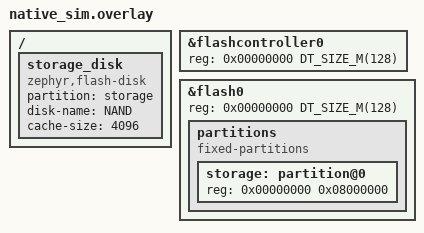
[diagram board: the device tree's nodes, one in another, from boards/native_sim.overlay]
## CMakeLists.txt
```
# SPDX-License-Identifier: Apache-2.0

cmake_minimum_required(VERSION 3.20.0)
find_package(Zephyr REQUIRED HINTS $ENV{ZEPHYR_BASE})
project(ext2tests)

FILE(GLOB app_sources src/*.c)
FILE(GLOB common_sources
  ../common/test_fs_util.c
  ../common/test_fs_mkfs.c
  ../common/test_fs_basic.c
  ../common/test_fs_dirops.c
  ../common/test_fs_open_flags.c
  ../common/test_fs_mount_flags.c
)
target_sources(app PRIVATE
  ${app_sources}
  ${common_sources}
)
```

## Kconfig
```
# SPDX-License-Identifier: Apache-2.0
# Copyright (c) 2023 Antmicro

mainmenu "Ext2 tests"

source "Kconfig.zephyr"

config APP_TEST_BIG
	bool "Make tests with larger file systems"
```

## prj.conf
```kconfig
CONFIG_FILE_SYSTEM=y
CONFIG_FILE_SYSTEM_EXT2=y
CONFIG_FILE_SYSTEM_MKFS=y

CONFIG_DISK_ACCESS=y
CONFIG_DISK_DRIVER_RAM=y

CONFIG_TEST_RANDOM_GENERATOR=y

CONFIG_ZTEST=y
CONFIG_ZTEST_STACK_SIZE=4096
```

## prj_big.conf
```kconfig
CONFIG_FILE_SYSTEM=y
CONFIG_FILE_SYSTEM_EXT2=y
CONFIG_FILE_SYSTEM_MKFS=y

CONFIG_DISK_ACCESS=y
CONFIG_DISK_DRIVER_RAM=y

CONFIG_EXT2_MAX_BLOCK_COUNT=20

CONFIG_TEST_RANDOM_GENERATOR=y

CONFIG_ZTEST=y
CONFIG_ZTEST_STACK_SIZE=4096

CONFIG_APP_TEST_BIG=y
```

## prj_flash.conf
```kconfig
CONFIG_FILE_SYSTEM=y
CONFIG_FILE_SYSTEM_EXT2=y
CONFIG_FILE_SYSTEM_MKFS=y

CONFIG_DISK_ACCESS=y
CONFIG_DISK_DRIVER_FLASH=y

CONFIG_TEST_RANDOM_GENERATOR=y

CONFIG_ZTEST=y
CONFIG_ZTEST_STACK_SIZE=4096
```

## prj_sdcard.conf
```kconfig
CONFIG_FILE_SYSTEM=y
CONFIG_FILE_SYSTEM_EXT2=y
CONFIG_FILE_SYSTEM_MKFS=y

CONFIG_SPI=y

CONFIG_DISK_ACCESS=y
CONFIG_DISK_DRIVER_SDMMC=y

CONFIG_EXT2_DISK_STARTING_SECTOR=34

CONFIG_TEST_RANDOM_GENERATOR=y

CONFIG_ZTEST=y
CONFIG_ZTEST_STACK_SIZE=4096
```

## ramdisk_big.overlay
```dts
/*
 * Copyright (c) 2023 Nordic Semiconductor ASA
 *
 * SPDX-License-Identifier: Apache-2.0
 */

/ {
	ramdisk0 {
		compatible = "zephyr,ram-disk";
		disk-name = "RAM";
		sector-size = <512>;
		sector-count = <18000>;
	};
};
```

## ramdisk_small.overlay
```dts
/*
 * Copyright (c) 2023 Nordic Semiconductor ASA
 *
 * SPDX-License-Identifier: Apache-2.0
 */

/ {
	ramdisk0 {
		compatible = "zephyr,ram-disk";
		disk-name = "RAM";
		sector-size = <512>;
		sector-count = <400>;
	};
};
```

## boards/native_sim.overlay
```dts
/*
 * Copyright (c) 2023 Antmicro
 *
 * SPDX-License-Identifier: Apache-2.0
 */

&flashcontroller0 {
	reg = <0x00000000 DT_SIZE_M(128)>;
};

&flash0 {
	reg = <0x00000000 DT_SIZE_M(128)>;
	partitions {
		compatible = "fixed-partitions";
		#address-cells = <1>;
		#size-cells = <1>;

		storage: partition@0 {
			reg = <0x00000000 0x08000000>;
		};
	};
};

/ {
	storage_disk {
		compatible = "zephyr,flash-disk";
		partition = <&storage>;
		disk-name = "NAND";
		cache-size = <4096>;
	};
};
```

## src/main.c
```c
/*
 * Copyright (c) 2023 Antmicro
 *
 * SPDX-License-Identifier: Apache-2.0
 */

#include <zephyr/ztest.h>
#include <zephyr/fs/fs.h>

#include "utils.h"

#ifdef CONFIG_DISK_DRIVER_RAM
	#define STORAGE_DEVICE "RAM"
#elif CONFIG_DISK_DRIVER_FLASH
	#define STORAGE_DEVICE "NAND"
#elif CONFIG_DISK_DRIVER_SDMMC
	#define STORAGE_DEVICE "SDMMC"
#endif

/* All tests must use this structure to mount file system. After each test this structure is cleaned
 * to allow for running next tests unaffected by previous one.
 */
struct fs_mount_t testfs_mnt = {
	.type = FS_EXT2,
	.mnt_point = "/sml",
	.storage_dev = STORAGE_DEVICE,
	.flags = 0,
};

static void before_test(void *f)
{
	ARG_UNUSED(f);

	zassert_equal(wipe_partition((uintptr_t)testfs_mnt.storage_dev), TC_PASS,
			"Failed to clean partition");
	testfs_mnt.flags = 0;
}

static void after_test(void *f)
{
	ARG_UNUSED(f);

	/* Unmount file system */
	fs_unmount(&testfs_mnt);
}

ZTEST_SUITE(ext2tests, NULL, NULL, before_test, after_test, NULL);
```

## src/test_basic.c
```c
/*
 * Copyright (c) 2023 Antmicro
 *
 * SPDX-License-Identifier: Apache-2.0
 */

#include <zephyr/ztest.h>
#include <zephyr/fs/fs.h>

#include "utils.h"

void test_fs_basic(void);

/* Expected by test_fs_basic() */
struct fs_mount_t *fs_basic_test_mp = &testfs_mnt;

ZTEST(ext2tests, test_basic)
{
	/* Common basic tests.
	 * (File system is mounted and unmounted during that test.)
	 */
	test_fs_basic();
}
```

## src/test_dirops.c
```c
/*
 * Copyright (c) 2023 Antmicro
 *
 * SPDX-License-Identifier: Apache-2.0
 */

#include <zephyr/ztest.h>
#include <zephyr/fs/fs.h>

#include "utils.h"

void test_fs_dirops(void);

/* Mount structure needed by test_fs_basic tests. */
struct fs_mount_t *fs_dirops_test_mp = &testfs_mnt;

ZTEST(ext2tests, test_dirops)
{
	struct fs_mount_t *mp = &testfs_mnt;
	struct fs_dirent de;

	zassert_equal(fs_mount(mp), 0, "Mount failed");

	/* 'lost+found' directory is created automatically. test_fs_dirops expects empty root
	 * directory hence we have to remove it before starting test.
	 */
	if (fs_stat("/sml/lost+found", &de) == 0) {
		zassert_equal(fs_unlink("/sml/lost+found"), 0, "unlink failed");
	}
	zassert_equal(fs_unmount(mp), 0, "Unount failed");

	/* Common dirops tests.
	 * (File system is mounted and unmounted during that test.)
	 */
	test_fs_dirops();
}
```

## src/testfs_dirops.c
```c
/*
 * Copyright (c) 2023 Antmicro
 *
 * SPDX-License-Identifier: Apache-2.0
 */

#include <zephyr/ztest.h>
#include <zephyr/fs/fs.h>

#include "utils.h"

ZTEST(ext2tests, test_dirops_basic)
{
	struct fs_mount_t *mp = &testfs_mnt;

	zassert_equal(fs_mount(mp), 0, "Mount failed");

	struct fs_file_t file;
	struct fs_dirent stat;

	fs_file_t_init(&file);

	/* Create some directories */
	zassert_equal(fs_mkdir("/sml/dir1"), 0, "Create dir1 failed");
	zassert_equal(fs_mkdir("/sml/dir2"), 0, "Create dir2 failed");

	/* Create some files */
	zassert_equal(fs_open(&file, "/sml/file1", FS_O_CREATE), 0, "Create file1 failed");
	zassert_equal(fs_close(&file), 0, "Close file error");
	zassert_equal(fs_open(&file, "/sml/dir1/file2", FS_O_CREATE), 0, "Create file2 failed");
	zassert_equal(fs_close(&file), 0, "Close file error");
	zassert_equal(fs_open(&file, "/sml/dir2/file3", FS_O_CREATE), 0, "Create file3 failed");
	zassert_equal(fs_close(&file), 0, "Close file error");

	/* Check if directories will open as files */
	zassert_equal(fs_open(&file, "/sml/dir1", 0), -EINVAL, "Should return error");
	zassert_equal(fs_open(&file, "/sml/dir2", 0), -EINVAL, "Should return error");

	/* Check directories with stat */
	zassert_equal(fs_stat("/sml/dir1", &stat), 0, "Stat dir1 failed");
	zassert_equal(stat.type, FS_DIR_ENTRY_DIR, "Wrong type");
	zassert_equal(stat.size, 0, "Wrong directory size");
	zassert_mem_equal(stat.name, "dir1", 5, "Wrong directory name");

	zassert_equal(fs_stat("/sml/dir2", &stat), 0, "Stat dir2 failed");
	zassert_equal(stat.type, FS_DIR_ENTRY_DIR, "Wrong type");
	zassert_equal(stat.size, 0, "Wrong directory size");
	zassert_mem_equal(stat.name, "dir2", 5, "Wrong directory name");

	/* Check if files will open correctly */
	zassert_equal(fs_open(&file, "/sml/file1", 0), 0, "Open file1 should succeed");
	zassert_equal(fs_close(&file), 0, "Close file error");
	zassert_equal(fs_open(&file, "/sml/dir1/file2", 0), 0, "Open file2 should succeed");
	zassert_equal(fs_close(&file), 0, "Close file error");
	zassert_equal(fs_open(&file, "/sml/dir2/file3", 0), 0, "Open file3 should succeed");
	zassert_equal(fs_close(&file), 0, "Close file error");

	/* Check files with stat */
	zassert_equal(fs_stat("/sml/file1", &stat), 0, "Stat file1 failed");
	zassert_equal(stat.type, FS_DIR_ENTRY_FILE, "Wrong type");
	zassert_equal(stat.size, 0, "Wrong file size");
	zassert_mem_equal(stat.name, "file1", 6, "Wrong file name");

	zassert_equal(fs_stat("/sml/dir1/file2", &stat), 0, "Stat file1 failed");
	zassert_equal(stat.type, FS_DIR_ENTRY_FILE, "Wrong type");
	zassert_equal(stat.size, 0, "Wrong file size");
	zassert_mem_equal(stat.name, "file2", 6, "Wrong file name");

	zassert_equal(fs_stat("/sml/dir2/file3", &stat), 0, "Stat file1 failed");
	zassert_equal(stat.type, FS_DIR_ENTRY_FILE, "Wrong type");
	zassert_equal(stat.size, 0, "Wrong file size");
	zassert_mem_equal(stat.name, "file3", 6, "Wrong file name");

	/* Check for some nonexisting files */
	zassert_equal(fs_open(&file, "/sml/file2", 0), -ENOENT, "Should not exist");
	zassert_equal(fs_open(&file, "/sml/file3", 0), -ENOENT, "Should not exist");
	zassert_equal(fs_open(&file, "/sml/dir1/file1", 0), -ENOENT, "Should not exist");
	zassert_equal(fs_open(&file, "/sml/dir1/file3", 0), -ENOENT, "Should not exist");
	zassert_equal(fs_open(&file, "/sml/dir2/file1", 0), -ENOENT, "Should not exist");
	zassert_equal(fs_open(&file, "/sml/dir2/file2", 0), -ENOENT, "Should not exist");

	zassert_equal(fs_unmount(mp), 0, "Unmount failed");
}
```

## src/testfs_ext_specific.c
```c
/*
 * Copyright (c) 2023 Antmicro
 *
 * SPDX-License-Identifier: Apache-2.0
 */

#include <zephyr/ztest.h>
#include <zephyr/fs/fs.h>
#include <zephyr/fs/ext2.h>
#include "utils.h"
#include "../../common/test_fs_util.h"

uint32_t calculate_blocks(uint32_t freeb, uint32_t B)
{
	uint32_t blocks = 0;

	if (freeb <= 12) {
		return freeb;
	}

	blocks += 12;
	freeb -= 12 + 1; /* direct blocks + top block of first level table */

	if (freeb <= B) {
		return blocks + freeb;
	}

	blocks += B;
	freeb -= B + 1; /* 1st level blocks + top block of second level table */

	if (freeb <= B * (B + 1)) {
		uint32_t n = freeb / (B + 1);
		uint32_t r = freeb % (B + 1);
		uint32_t partial = r > 0 ? 1 : 0;

		return blocks + n * B + r - partial;
	}
	return blocks;
	/* TODO: revisit this and extend when 3rd level blocks will be possible */
}

static void write_to_file(const char *file_path, uint32_t bytes_to_write)
{
	int64_t ret = 0;
	struct fs_file_t file;
	struct fs_dirent entry;

	fs_file_t_init(&file);
	ret = fs_open(&file, file_path, FS_O_RDWR | FS_O_CREATE);
	zassert_equal(ret, 0, "File open failed (ret=%d)", ret);

	ret = testfs_write_incrementing(&file, 0, bytes_to_write);
	zassert_equal(ret, bytes_to_write, "Different number of bytes written %ld (expected %ld)",
			ret, bytes_to_write);

	ret = fs_close(&file);
	zassert_equal(ret, 0, "File close failed (ret=%d)", ret);


	/* Check file size */
	ret = fs_stat(file_path, &entry);
	zassert_equal(ret, 0, "File stat failed (ret=%d)", ret);
	zassert_equal(entry.size, bytes_to_write,
			"Wrong file size %d (expected %d)", entry.size,
			bytes_to_write);

	fs_file_t_init(&file);
	ret = fs_open(&file, file_path, FS_O_READ);
	zassert_equal(ret, 0, "File open failed (ret=%d)", ret);


	ret = testfs_verify_incrementing(&file, 0, bytes_to_write);
	zassert_equal(ret, bytes_to_write, "Different number of bytes read %ld (expected %ld)",
			ret, bytes_to_write);

	ret = fs_close(&file);
	zassert_equal(ret, 0, "File close failed (ret=%d)", ret);
}

static void truncate_file(const char *file_path, uint32_t new_size)
{
	int64_t ret = 0;
	struct fs_file_t file;
	struct fs_dirent entry;

	fs_file_t_init(&file);

	TC_PRINT("Truncating to %d\n", new_size);

	ret = fs_open(&file, file_path, FS_O_RDWR);
	zassert_equal(ret, 0, "File open failed (ret=%d)", ret);

	ret = fs_truncate(&file, new_size);
	zassert_equal(ret, 0, "File truncate failed (ret=%d)", ret);

	ret = fs_stat(file_path, &entry);
	zassert_equal(ret, 0, "File stat failed (ret=%d)", ret);
	zassert_equal(entry.size, new_size,
			"Wrong file size %d (expected %d)", entry.size, new_size);

	ret = fs_seek(&file, 0, FS_SEEK_SET);
	zassert_equal(ret, 0, "File seek failed (ret=%d)", ret);

	ret = testfs_verify_incrementing(&file, 0, new_size);
	zassert_equal(ret, new_size, "Different number of bytes read %ld (expected %ld)",
			ret, new_size);

	ret = fs_close(&file);
	zassert_equal(ret, 0, "File close failed (ret=%d)", ret);
}

void writing_test(struct ext2_cfg *config)
{
	int64_t ret = 0;
	struct fs_statvfs sbuf;
	struct fs_mount_t *mp = &testfs_mnt;
	static const char *file_path = "/sml/file";

	ret = fs_mkfs(FS_EXT2, (uintptr_t)mp->storage_dev, config, 0);
	zassert_equal(ret, 0, "Failed to mkfs with 2K blocks");

	mp->flags = FS_MOUNT_FLAG_NO_FORMAT;
	ret = fs_mount(mp);
	zassert_equal(ret, 0, "Mount failed (ret=%d)", ret);

	ret = fs_statvfs(mp->mnt_point, &sbuf);
	zassert_equal(ret, 0, "Expected success (ret=%d)", ret);

	/* Calculate how many numbers will be written (use all available memory) */
	uint32_t freeb = sbuf.f_bfree;
	uint32_t bsize = sbuf.f_bsize;
	uint32_t available_blocks = calculate_blocks(freeb, bsize / sizeof(uint32_t));

	uint32_t bytes_to_write = bsize * available_blocks;

	TC_PRINT("Available blocks: %d\nBlock size: %d\nBytes_to_write: %d\n",
			available_blocks, bsize, bytes_to_write);

	write_to_file(file_path, bytes_to_write);

	uint32_t new_size = bytes_to_write;

	while (new_size > 1) {
		new_size = new_size / 8 * 3;
		truncate_file(file_path, new_size);
	}

	ret = fs_unmount(mp);
	zassert_equal(ret, 0, "Unmount failed (ret=%d)", ret);
}

ZTEST(ext2tests, test_indirect_block_removal)
{
	int64_t ret = 0;
	struct fs_statvfs sbuf;
	struct fs_mount_t *mp = &testfs_mnt;
	static const char *file_path = "/sml/file";

	ret = fs_mkfs(FS_EXT2, (uintptr_t)mp->storage_dev, NULL, 0);
	zassert_equal(ret, 0, "Failed to mkfs with 2K blocks");

	mp->flags = FS_MOUNT_FLAG_NO_FORMAT;
	ret = fs_mount(mp);
	zassert_equal(ret, 0, "Mount failed (ret=%d)", ret);

	ret = fs_statvfs(mp->mnt_point, &sbuf);
	zassert_equal(ret, 0, "Expected success (ret=%d)", ret);

	uint32_t bsize = sbuf.f_bsize;

	uint32_t bytes_to_write = bsize * 13;

	TC_PRINT("Block size: %d\nBytes_to_write: %d\n", bsize, bytes_to_write);

	write_to_file(file_path, bytes_to_write);

	/* First truncate will remove all blocks under first indirect block.
	 * Second truncate will remove rest of blocks;
	 * it will check if first indirect block was removed properly.
	 */
	uint32_t sizes[] = {12 * bsize, 0};

	for (int i = 0; i < ARRAY_SIZE(sizes); i++) {
		uint32_t new_size = sizes[i];

		truncate_file(file_path, new_size);
	}

	ret = fs_unmount(mp);
	zassert_equal(ret, 0, "Unmount failed (ret=%d)", ret);
}

ZTEST(ext2tests, test_write_big_file)
{
	writing_test(NULL);
}

#if defined(CONFIG_APP_TEST_BIG)
ZTEST(ext2tests, test_write_big_file_2K)
{
	struct ext2_cfg config = {
		.block_size = 2048,
		.fs_size = 0x2000000,
		.bytes_per_inode = 0,
		.volume_name[0] = 0,
		.set_uuid = false,
	};

	writing_test(&config);
}

ZTEST(ext2tests, test_write_big_file_4K)
{
	struct ext2_cfg config = {
		.block_size = 4096,
		.fs_size = 0x8000000,
		.bytes_per_inode = 0,
		.volume_name[0] = 0,
		.set_uuid = false,
	};

	writing_test(&config);
}
#endif
```

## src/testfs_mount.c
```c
/*
 * Copyright (c) 2023 Antmicro
 *
 * SPDX-License-Identifier: Apache-2.0
 */

#include <zephyr/ztest.h>
#include <zephyr/fs/fs.h>
#include <zephyr/fs/ext2.h>
#include "utils.h"

ZTEST(ext2tests, test_mount_only)
{
	struct fs_mount_t *mp = &testfs_mnt;
	int ret = 0;

	/* Test FS_MOUNT_FLAG_NO_FORMAT flag */
	mp->flags |= FS_MOUNT_FLAG_NO_FORMAT;
	ret = fs_mount(mp);
	TC_PRINT("Mount unformatted with FS_MOUNT_FLAG_NO_FORMAT set\n");
	zassert_false(ret == 0, "Expected failure (ret=%d)", ret);

	/* Test FS_MOUNT_FLAG_READ_ONLY on non-formatted volume*/
	mp->flags = FS_MOUNT_FLAG_READ_ONLY;
	ret = fs_mount(mp);
	TC_PRINT("Mount unformatted with FS_MOUNT_FLAG_READ_ONLY set\n");
	zassert_false(ret == 0, "Expected failure (ret=%d)", ret);

	/* Format volume and add some files/dirs to check read-only flag */
	mp->flags = 0;
	ret = fs_mount(mp);
	TC_PRINT("Mount again to format volume\n");
	zassert_equal(ret, 0, "Expected success (ret=%d)", ret);
	TC_PRINT("Create some file\n");

	ret = fs_unmount(mp);
	zassert_equal(ret, 0, "Expected success (ret=%d)", ret);

	/* Check fs operation on volume mounted with FS_MOUNT_FLAG_READ_ONLY */
	mp->flags = FS_MOUNT_FLAG_READ_ONLY;
	TC_PRINT("Mount as read-only\n");
	ret = fs_mount(mp);
	zassert_equal(ret, 0, "Expected success (ret=%d)", ret);

	ret = fs_unmount(mp);
	zassert_equal(ret, 0, "Expected success (ret=%d)", ret);
}

ZTEST(ext2tests, test_statvfs)
{
	int ret = 0;
	struct fs_statvfs sbuf;
	struct fs_mount_t *mp = &testfs_mnt;
	size_t partition_size = MIN(0x800000, get_partition_size((uintptr_t)mp->storage_dev));

	mp->flags = 0;
	ret = fs_mount(mp);
	zassert_equal(ret, 0, "Expected success (ret=%d)", ret);

	ret = fs_statvfs(mp->mnt_point, &sbuf);
	zassert_equal(ret, 0, "Expected success (ret=%d)", ret);

	TC_PRINT("Mounted file system: bsize:%lu frsize:%lu blocks:%lu, bfree:%lu\n",
			sbuf.f_bsize, sbuf.f_frsize, sbuf.f_blocks, sbuf.f_bfree);

	zassert_equal(sbuf.f_bsize, 1024,
			"Wrong block size %lu (expected %lu)", sbuf.f_bsize, 1024);
	zassert_equal(sbuf.f_frsize, 1024,
			"Wrong frag size %lu (expected %lu)", sbuf.f_frsize, 1024);
	zassert_equal(sbuf.f_blocks, partition_size / 1024,
			"Wrong block count %lu (expected %lu)",
			sbuf.f_blocks, partition_size / 1024);

	ret = fs_unmount(mp);
	zassert_equal(ret, 0, "Expected success (ret=%d)", ret);
}

/* Tests from common directory */

void test_fs_mkfs_simple(void);

/* Global variables expected by tests */
struct fs_mount_t *fs_mkfs_mp = &testfs_mnt;
const int fs_mkfs_type = FS_EXT2;
uintptr_t fs_mkfs_dev_id;
int fs_mkfs_flags;

ZTEST(ext2tests, test_mkfs_simple)
{
	struct fs_mount_t *mp = &testfs_mnt;

	fs_mkfs_dev_id = (uintptr_t) mp->storage_dev;
	fs_mkfs_flags = 0;
	test_fs_mkfs_simple();
}

void mkfs_custom_config(struct ext2_cfg *cfg)
{
	int ret = 0;
	struct fs_statvfs sbuf;
	struct fs_mount_t *mp = &testfs_mnt;
	size_t partition_size = MIN(cfg->fs_size, get_partition_size((uintptr_t)mp->storage_dev));

	ret = fs_mkfs(FS_EXT2, (uintptr_t)mp->storage_dev, cfg, 0);
	zassert_equal(ret, 0, "Failed to mkfs with 2K blocks");

	mp->flags = FS_MOUNT_FLAG_NO_FORMAT;
	ret = fs_mount(mp);
	zassert_equal(ret, 0, "Mount failed (ret=%d)", ret);

	ret = fs_statvfs(mp->mnt_point, &sbuf);
	zassert_equal(ret, 0, "Statvfs failed (ret=%d)", ret);

	TC_PRINT("Mounted file system: bsize:%lu frsize:%lu blocks:%lu, bfree:%lu\n",
			sbuf.f_bsize, sbuf.f_frsize, sbuf.f_blocks, sbuf.f_bfree);

	zassert_equal(sbuf.f_bsize, cfg->block_size,
			"Wrong block size %lu (expected %lu)", sbuf.f_bsize, cfg->block_size);
	zassert_equal(sbuf.f_frsize, cfg->block_size,
			"Wrong frag size %lu (expected %lu)", sbuf.f_frsize, cfg->block_size);
	zassert_equal(sbuf.f_blocks, partition_size / cfg->block_size,
			"Wrong block count %lu (expected %lu)",
			sbuf.f_blocks, partition_size / cfg->block_size);

	ret = fs_unmount(mp);
	zassert_equal(ret, 0, "Unmount failed (ret=%d)", ret);
}

#if defined(CONFIG_APP_TEST_BIG)
ZTEST(ext2tests, test_mkfs_custom_2K)
{
	struct ext2_cfg config = {
		.block_size = 2048,
		.fs_size = 0x2000000,
		.bytes_per_inode = 0,
		.volume_name[0] = 0,
		.set_uuid = false,
	};

	mkfs_custom_config(&config);
}

ZTEST(ext2tests, test_mkfs_custom_4K)
{
	struct ext2_cfg config = {
		.block_size = 4096,
		.fs_size = 0x8000000,
		.bytes_per_inode = 0,
		.volume_name[0] = 0,
		.set_uuid = false,
	};

	mkfs_custom_config(&config);
}
#endif
```

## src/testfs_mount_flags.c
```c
/*
 * Copyright (c) 2023 Antmicro
 *
 * SPDX-License-Identifier: Apache-2.0
 */

#include <zephyr/ztest.h>
#include <zephyr/fs/fs.h>
#include <zephyr/fs/ext2.h>

#include "utils.h"

void test_fs_mount_flags(void);

/* Global variable expected by tests */
struct fs_mount_t *mount_flags_mp = &testfs_mnt;

ZTEST(ext2tests, test_mount_flags)
{
	test_fs_mount_flags();
}
```

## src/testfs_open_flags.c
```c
/*
 * Copyright (c) 2023 Antmicro
 *
 * SPDX-License-Identifier: Apache-2.0
 */

#include <zephyr/ztest.h>
#include <zephyr/fs/fs.h>
#include <zephyr/fs/ext2.h>

#include "utils.h"

void test_fs_open_flags(void);

/* Expected by test_fs_open_flags() */
const char *test_fs_open_flags_file_path = "/sml/open_flags_file";

ZTEST(ext2tests, test_open_flags)
{
	struct fs_mount_t *mp = &testfs_mnt;

	zassert_equal(fs_mount(mp), 0, "Failed to mount partition");

	test_fs_open_flags();

	zassert_equal(fs_unmount(mp), 0, "Failed to unmount partition");
}

ZTEST(ext2tests, test_open_flags_2K)
{
	int ret = 0;
	struct fs_mount_t *mp = &testfs_mnt;
	struct ext2_cfg ext2_config = {
		.block_size = 2048,
		.fs_size = 0x2000000,
		.bytes_per_inode = 0,
		.volume_name[0] = 0,
		.set_uuid = false,
	};

	ret = fs_mkfs(FS_EXT2, (uintptr_t)mp->storage_dev, &ext2_config, 0);
	zassert_equal(ret, 0, "Failed to mkfs with 2K blocks");

	mp->flags = FS_MOUNT_FLAG_NO_FORMAT;
	zassert_equal(fs_mount(mp), 0, "Failed to mount partition");

	test_fs_open_flags();

	zassert_equal(fs_unmount(mp), 0, "Failed to unmount partition");
}

#if defined(CONFIG_APP_TEST_BIG)
ZTEST(ext2tests, test_open_flags_4K)
{
	int ret = 0;
	struct fs_mount_t *mp = &testfs_mnt;
	struct ext2_cfg ext2_config = {
		.block_size = 4096,
		.fs_size = 0x8000000,
		.bytes_per_inode = 0,
		.volume_name[0] = 0,
		.set_uuid = false,
	};

	ret = fs_mkfs(FS_EXT2, (uintptr_t)mp->storage_dev, &ext2_config, 0);
	zassert_equal(ret, 0, "Failed to mkfs with 2K blocks");

	mp->flags = FS_MOUNT_FLAG_NO_FORMAT;
	zassert_equal(fs_mount(mp), 0, "Failed to mount partition");

	test_fs_open_flags();

	zassert_equal(fs_unmount(mp), 0, "Failed to unmount partition");
}
#endif
```

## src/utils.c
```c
/*
 * Copyright (c) 2023 Antmicro
 *
 * SPDX-License-Identifier: Apache-2.0
 */

#include <zephyr/ztest.h>
#include <zephyr/fs/fs.h>
#include <zephyr/storage/disk_access.h>

#include "utils.h"

static int sectors_info(const char *disk, uint32_t *ss, uint32_t *sc)
{
	int rc;

	rc = disk_access_ioctl(disk, DISK_IOCTL_GET_SECTOR_COUNT, sc);
	if (rc < 0) {
		TC_PRINT("Disk access (sector count) error: %d", rc);
		return rc;
	}

	rc = disk_access_ioctl(disk, DISK_IOCTL_GET_SECTOR_SIZE, ss);
	if (rc < 0) {
		TC_PRINT("Disk access (sector size) error: %d", rc);
		return rc;
	}

	return 0;
}

int wipe_partition(uintptr_t id)
{
	int rc;
	const char *name = (const char *)id;
	uint32_t sector_count, sector_size;

	TC_PRINT("Wiping %s\n", name);

	rc = disk_access_init(name);
	if (rc < 0) {
		return rc;
	}

	rc = sectors_info(name, &sector_size, &sector_count);
	if (rc < 0) {
		return rc;
	}

	uint8_t zeros[sector_size];

	memset(zeros, 0, sector_size);

	/* Superblock is located at offset 1024B and has size 1024B */
	uint32_t start_sector = CONFIG_EXT2_DISK_STARTING_SECTOR + 1024 / sector_size;
	uint32_t num_sectors = 1024 / sector_size + (1024 % sector_size != 0);

	for (uint32_t i = 0; i < num_sectors; i++) {
		rc = disk_access_write(name, zeros, start_sector + i, 1);
		if (rc < 0) {
			return rc;
		}
	}

	return 0;
}

size_t get_partition_size(uintptr_t id)
{
	const char *name = (const char *)id;
	uint32_t sector_count, sector_size;

	sectors_info(name, &sector_size, &sector_count);

	/* Assume that partition occupies sectors from CONFIG_EXT2_DISK_STARTING_SECTOR to last. */
	return sector_size * (sector_count - CONFIG_EXT2_DISK_STARTING_SECTOR);
}
```

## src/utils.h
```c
/*
 * Copyright (c) 2023 Antmicro
 *
 * SPDX-License-Identifier: Apache-2.0
 */

#ifndef __TESTS_FS_EXT2_UTILS_H__
#define __TESTS_FS_EXT2_UTILS_H__

extern struct fs_mount_t testfs_mnt;

int wipe_partition(uintptr_t id);
size_t get_partition_size(uintptr_t id);

#endif /* __TESTS_FS_EXT2_UTILS_H__ */
```
